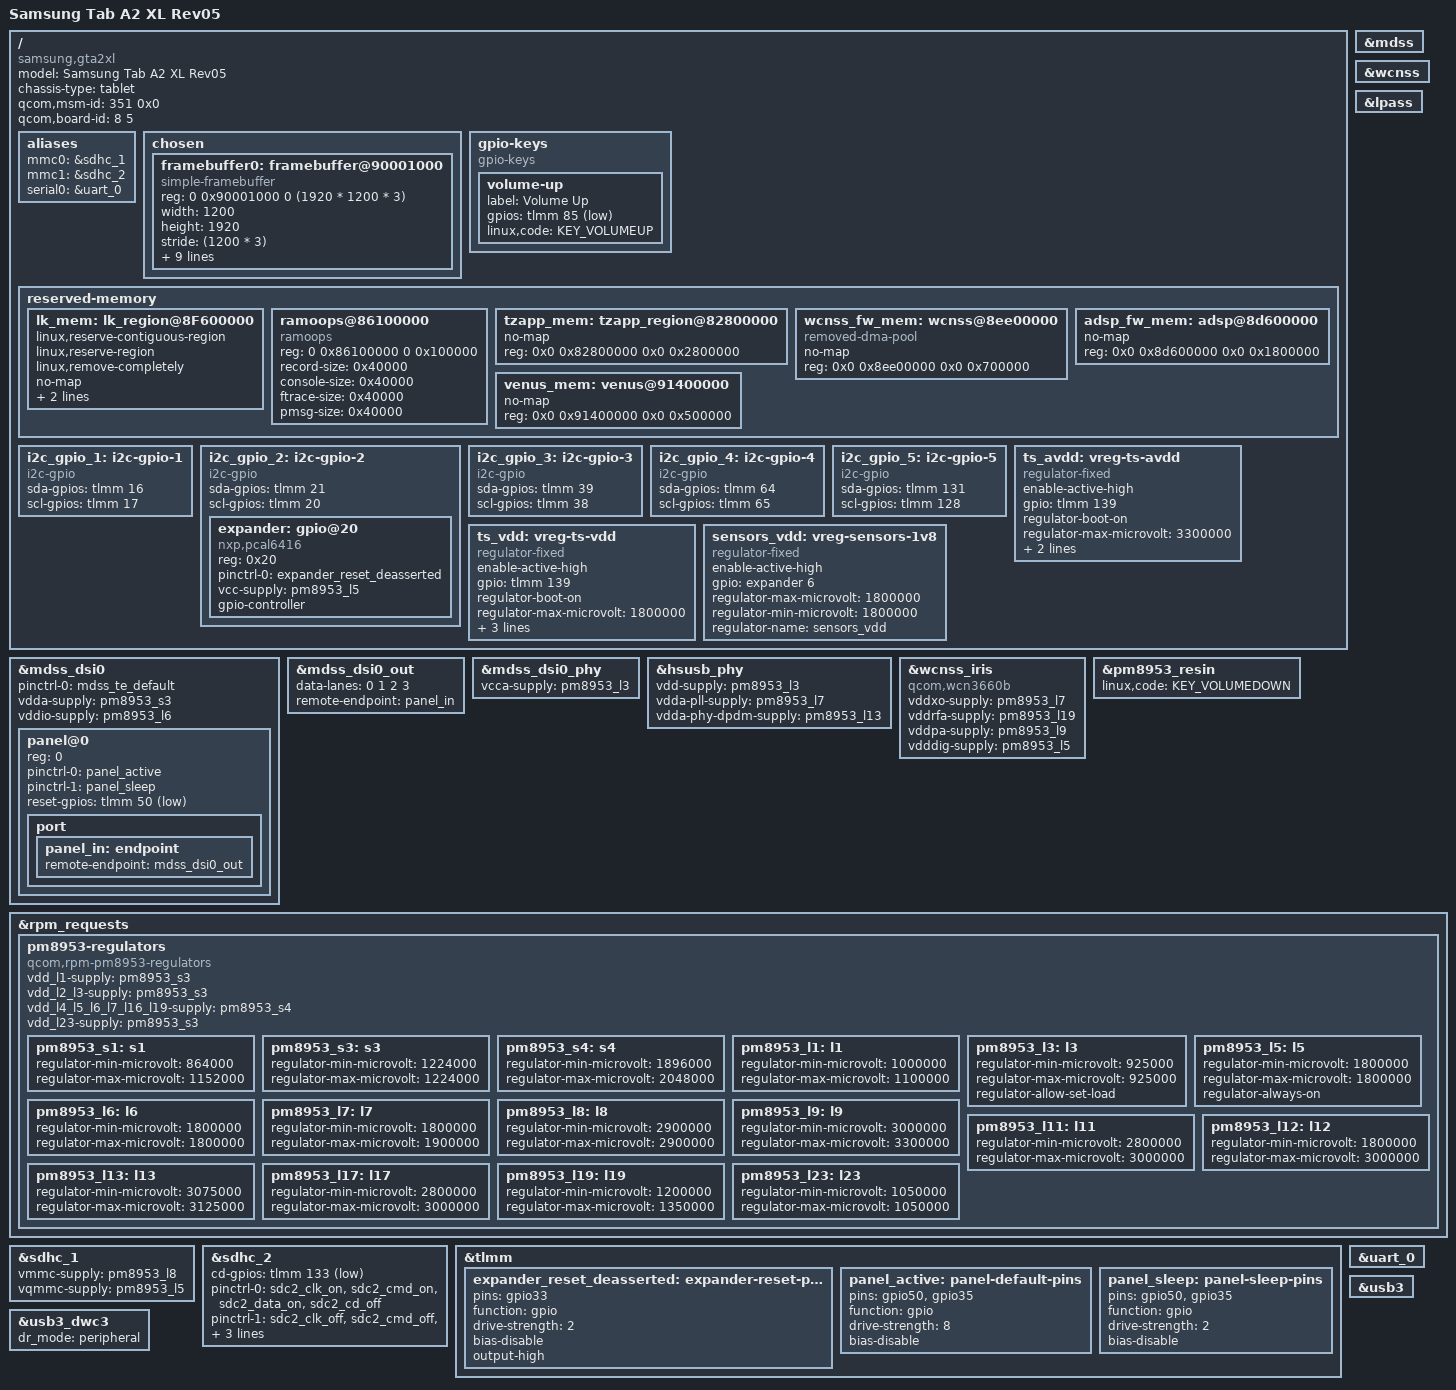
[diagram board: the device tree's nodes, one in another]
// SPDX-License-Identifier: BSD-3-Clause
/*
 * Copyright (c) 2024, Bassusteur
 */
/dts-v1/;

#include "sdm450.dtsi"
#include "msm8953.dtsi"
#include "pm8953.dtsi"
#include <dt-bindings/leds/common.h>

/ {
	model = "Samsung Tab A2 XL Rev05";
	compatible = "samsung,gta2xl", "qcom,sdm450";
	chassis-type = "tablet";
	qcom,msm-id = <351 0x0>;
	qcom,board-id = <8 5>;

	aliases {
		mmc0 = &sdhc_1;
		mmc1 = &sdhc_2;
		serial0 = &uart_0;
	};

	chosen {
		#address-cells = <2>;
		#size-cells = <2>;
		ranges;

		framebuffer0: framebuffer@90001000 {
			compatible = "simple-framebuffer";
			reg = <0 0x90001000 0 (1920 * 1200 * 3)>;

			width = <1200>;
			height = <1920>;
			stride = <(1200 * 3)>;
			format = "r8g8b8";

			power-domains = <&gcc MDSS_GDSC>;

			clocks = <&gcc GCC_MDSS_AHB_CLK>,
				 <&gcc GCC_MDSS_AXI_CLK>,
				 <&gcc GCC_MDSS_VSYNC_CLK>,
				 <&gcc GCC_MDSS_MDP_CLK>,
				 <&gcc GCC_MDSS_BYTE0_CLK>,
				 <&gcc GCC_MDSS_PCLK0_CLK>,
				 <&gcc GCC_MDSS_ESC0_CLK>;
		};
	};

	gpio-keys {
		compatible = "gpio-keys";

		volume-up {
			label = "Volume Up";
			gpios = <&tlmm 85 GPIO_ACTIVE_LOW>;
			linux,code = <KEY_VOLUMEUP>;
		};
	};

	reserved-memory {
		lk_mem: lk_region@8F600000 {
			linux,reserve-contiguous-region;
			linux,reserve-region;
			linux,remove-completely;
			no-map;
			reg = <0x0 0x8F600000 0x0 0x00300000>;
			label = "lk_mem";
		};

		ramoops@86100000 {
			compatible = "ramoops";
			reg = <0 0x86100000 0 0x100000>;
			record-size = <0x40000>;
			console-size = <0x40000>;
			ftrace-size = <0x40000>;
			pmsg-size = <0x40000>;
		};

		tzapp_mem: tzapp_region@82800000 {
			no-map;
			reg = <0x0 0x82800000 0x0 0x2800000>;
		};

		/delete-node/ wcnss@8e700000;
		wcnss_fw_mem:  wcnss@8ee00000 {
			compatible = "removed-dma-pool";
			no-map;
			reg = <0x0 0x8ee00000 0x0 0x700000>;
		};

		/delete-node/ adsp@8d600000;
		adsp_fw_mem: adsp@8d600000 {
    			no-map;
    			reg = <0x0 0x8d600000 0x0 0x1800000>;
		};

		/delete-node/ venus@91400000;
		venus_mem: venus@91400000 {
			no-map;
			reg = <0x0 0x91400000 0x0 0x500000>;
		};
	};

	i2c_gpio_1: i2c-gpio-1 {
		compatible = "i2c-gpio";
		sda-gpios = <&tlmm 16 (GPIO_ACTIVE_HIGH|GPIO_OPEN_DRAIN)>;
		scl-gpios = <&tlmm 17 (GPIO_ACTIVE_HIGH|GPIO_OPEN_DRAIN)>;

		#address-cells = <1>;
		#size-cells = <0>;
	};

	i2c_gpio_2: i2c-gpio-2 {
		compatible = "i2c-gpio";
		sda-gpios = <&tlmm 21 (GPIO_ACTIVE_HIGH|GPIO_OPEN_DRAIN)>;
		scl-gpios = <&tlmm 20 (GPIO_ACTIVE_HIGH|GPIO_OPEN_DRAIN)>;

		#address-cells = <1>;
		#size-cells = <0>;
	};

	i2c_gpio_3: i2c-gpio-3 {
		compatible = "i2c-gpio";
		sda-gpios = <&tlmm 39 (GPIO_ACTIVE_HIGH|GPIO_OPEN_DRAIN)>;
		scl-gpios = <&tlmm 38 (GPIO_ACTIVE_HIGH|GPIO_OPEN_DRAIN)>;

		#address-cells = <1>;
		#size-cells = <0>;
	};

	i2c_gpio_4: i2c-gpio-4 {
		compatible = "i2c-gpio";
		sda-gpios = <&tlmm 64 (GPIO_ACTIVE_HIGH|GPIO_OPEN_DRAIN)>;
		scl-gpios = <&tlmm 65 (GPIO_ACTIVE_HIGH|GPIO_OPEN_DRAIN)>;

		#address-cells = <1>;
		#size-cells = <0>;
	};

	i2c_gpio_5: i2c-gpio-5 {
		compatible = "i2c-gpio";
		sda-gpios = <&tlmm 131 (GPIO_ACTIVE_HIGH|GPIO_OPEN_DRAIN)>;
		scl-gpios = <&tlmm 128 (GPIO_ACTIVE_HIGH|GPIO_OPEN_DRAIN)>;

		#address-cells = <1>;
		#size-cells = <0>;
	};

	ts_avdd: vreg-ts-avdd {
		compatible = "regulator-fixed";

		enable-active-high;
		gpio = <&tlmm 139 GPIO_ACTIVE_HIGH>;
		regulator-boot-on;
		regulator-max-microvolt = <3300000>;
		regulator-min-microvolt = <3300000>;
		regulator-name = "ts_avdd";
	};

	ts_vdd: vreg-ts-vdd {
		compatible = "regulator-fixed";

		enable-active-high;
		gpio = <&tlmm 139 GPIO_ACTIVE_HIGH>;
		regulator-boot-on;
		regulator-max-microvolt = <1800000>;
		regulator-min-microvolt = <1800000>;
		regulator-name = "ts_vdd";
		vin-supply = <&pm8953_s4>;
	};

	sensors_vdd: vreg-sensors-1v8 {
		compatible = "regulator-fixed";

		enable-active-high;
		gpio = <&expander 6 GPIO_ACTIVE_HIGH>;
		regulator-max-microvolt = <1800000>;
		regulator-min-microvolt = <1800000>;
		regulator-name = "sensors_vdd";
	};

};

&mdss {
    status = "okay";
};

&mdss_dsi0 {
	status = "okay";

	pinctrl-names = "default";
	pinctrl-0 = <&mdss_te_default>;

	vdda-supply = <&pm8953_s3>;
	vddio-supply = <&pm8953_l6>;

	panel@0 {
		compatible = "";
		reg = <0>;

		pinctrl-0 = <&panel_active>;
		pinctrl-1 = <&panel_sleep>;
		pinctrl-names = "default", "sleep";

		reset-gpios = <&tlmm 50 GPIO_ACTIVE_LOW>;

		port {
			panel_in: endpoint {
				remote-endpoint = <&mdss_dsi0_out>;
			};
		};
	};
};

&mdss_dsi0_out {
	data-lanes = <0 1 2 3>;
	remote-endpoint = <&panel_in>;
};

&mdss_dsi0_phy {
    	status = "okay";
	vcca-supply = <&pm8953_l3>;
};

&hsusb_phy {
	status = "okay";

	vdd-supply = <&pm8953_l3>;
	vdda-pll-supply = <&pm8953_l7>;
	vdda-phy-dpdm-supply = <&pm8953_l13>;
};

&i2c_gpio_2 {
	expander: gpio@20 {
		compatible = "nxp,pcal6416";
		reg = <0x20>;

		pinctrl-0 = <&expander_reset_deasserted>;
		pinctrl-names = "default";

		vcc-supply = <&pm8953_l5>;

		gpio-controller;
	#gpio-cells = <2>;
	};
};

&wcnss {
    status = "okay";
};

&wcnss_fw_mem {
    status = "okay";
};

&wcnss_iris {
	compatible = "qcom,wcn3660b";
	vddxo-supply = <&pm8953_l7>;
	vddrfa-supply = <&pm8953_l19>;
	vddpa-supply = <&pm8953_l9>;
	vdddig-supply = <&pm8953_l5>;
};

&lpass {
	status = "okay";
};

&pm8953_resin {
	status = "okay";
	linux,code = <KEY_VOLUMEDOWN>;
};


&rpm_requests {
	pm8953-regulators {
		compatible = "qcom,rpm-pm8953-regulators";

		vdd_l1-supply = <&pm8953_s3>;
		vdd_l2_l3-supply = <&pm8953_s3>;
		vdd_l4_l5_l6_l7_l16_l19-supply = <&pm8953_s4>;
		vdd_l23-supply = <&pm8953_s3>;

		pm8953_s1: s1 {
			regulator-min-microvolt = <864000>;
			regulator-max-microvolt = <1152000>;
		};

		pm8953_s3: s3 {
			regulator-min-microvolt = <1224000>;
			regulator-max-microvolt = <1224000>;
		};

		pm8953_s4: s4 {
			regulator-min-microvolt = <1896000>;
			regulator-max-microvolt = <2048000>;
		};

		pm8953_l1: l1 {
			regulator-min-microvolt = <1000000>;
			regulator-max-microvolt = <1100000>;
		};

		pm8953_l3: l3 {
			regulator-min-microvolt = <925000>;
			regulator-max-microvolt = <925000>;
			regulator-allow-set-load;
		};

		pm8953_l5: l5 {
			regulator-min-microvolt = <1800000>;
			regulator-max-microvolt = <1800000>;
			regulator-always-on;
		};

		pm8953_l6: l6 {
			regulator-min-microvolt = <1800000>;
			regulator-max-microvolt = <1800000>;
		};

		pm8953_l7: l7 {
			regulator-min-microvolt = <1800000>;
			regulator-max-microvolt = <1900000>;
		};

		pm8953_l8: l8 {
			regulator-min-microvolt = <2900000>;
			regulator-max-microvolt = <2900000>;
		};

		pm8953_l9: l9 {
			regulator-min-microvolt = <3000000>;
			regulator-max-microvolt = <3300000>;
		};

		pm8953_l11: l11 {
			regulator-min-microvolt = <2800000>;
			regulator-max-microvolt = <3000000>;
		};

		pm8953_l12: l12 {
			regulator-min-microvolt = <1800000>;
			regulator-max-microvolt = <3000000>;
		};

		pm8953_l13: l13 {
			regulator-min-microvolt = <3075000>;
			regulator-max-microvolt = <3125000>;
		};

		pm8953_l17: l17 {
			regulator-min-microvolt = <2800000>;
			regulator-max-microvolt = <3000000>;
		};

		pm8953_l19: l19 {
			regulator-min-microvolt = <1200000>;
			regulator-max-microvolt = <1350000>;
		};

		pm8953_l23: l23 {
			regulator-min-microvolt = <1050000>;
			regulator-max-microvolt = <1050000>;
		};
	};
};

&sdhc_1 {
	status = "okay";

	vmmc-supply = <&pm8953_l8>;
	vqmmc-supply = <&pm8953_l5>;
};

&sdhc_2 {
	status = "okay";

	cd-gpios = <&tlmm 133 GPIO_ACTIVE_LOW>;

	pinctrl-names = "default", "sleep";
	pinctrl-0 = <&sdc2_clk_on &sdc2_cmd_on &sdc2_data_on &sdc2_cd_off>;
	pinctrl-1 = <&sdc2_clk_off &sdc2_cmd_off &sdc2_data_off &sdc2_cd_off>;

	vmmc-supply = <&pm8953_l11>;
	vqmmc-supply = <&pm8953_l12>;
};

&tlmm {
	expander_reset_deasserted: expander-reset-pins {
		pins = "gpio33";
		function = "gpio";
		drive-strength = <2>;
		bias-disable;
		output-high;
	};

	panel_active: panel-default-pins {
		pins = "gpio50", "gpio35";
		function = "gpio";
		drive-strength = <8>;
		bias-disable;
	};

	panel_sleep: panel-sleep-pins {
		pins = "gpio50", "gpio35";
		function = "gpio";
		drive-strength = <2>;
		bias-disable;
	};
};

&uart_0 {
	status = "okay";
};

&usb3 {
	status = "okay";
};

&usb3_dwc3 {
	dr_mode = "peripheral";
};
